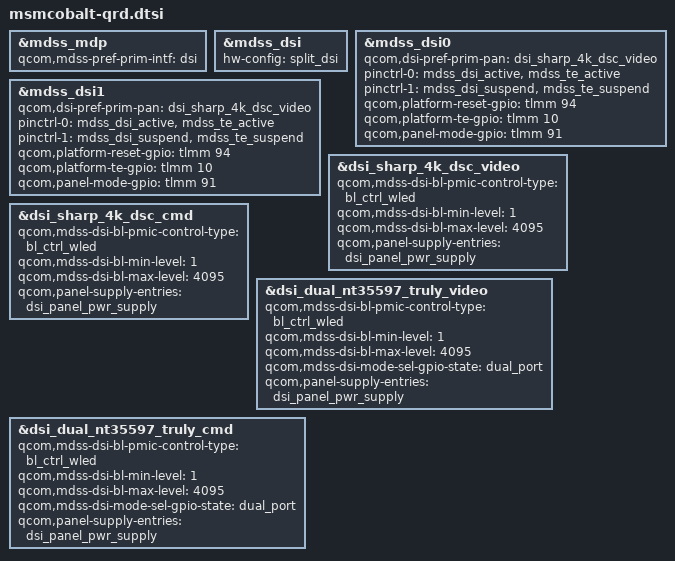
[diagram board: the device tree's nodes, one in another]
/* Copyright (c) 2016, The Linux Foundation. All rights reserved.
 *
 * This program is free software; you can redistribute it and/or modify
 * it under the terms of the GNU General Public License version 2 and
 * only version 2 as published by the Free Software Foundation.
 *
 * This program is distributed in the hope that it will be useful,
 * but WITHOUT ANY WARRANTY; without even the implied warranty of
 * MERCHANTABILITY or FITNESS FOR A PARTICULAR PURPOSE.  See the
 * GNU General Public License for more details.
 */

#include "msmcobalt-mtp.dtsi"

&mdss_mdp {
	qcom,mdss-pref-prim-intf = "dsi";
};

&mdss_dsi {
	hw-config = "split_dsi";
};

&mdss_dsi0 {
	qcom,dsi-pref-prim-pan = <&dsi_sharp_4k_dsc_video>;
	pinctrl-names = "mdss_default", "mdss_sleep";
	pinctrl-0 = <&mdss_dsi_active &mdss_te_active>;
	pinctrl-1 = <&mdss_dsi_suspend &mdss_te_suspend>;
	qcom,platform-reset-gpio = <&tlmm 94 0>;
	qcom,platform-te-gpio = <&tlmm 10 0>;
	qcom,panel-mode-gpio = <&tlmm 91 0>;
};

&mdss_dsi1 {
	qcom,dsi-pref-prim-pan = <&dsi_sharp_4k_dsc_video>;
	pinctrl-names = "mdss_default", "mdss_sleep";
	pinctrl-0 = <&mdss_dsi_active &mdss_te_active>;
	pinctrl-1 = <&mdss_dsi_suspend &mdss_te_suspend>;
	qcom,platform-reset-gpio = <&tlmm 94 0>;
	qcom,platform-te-gpio = <&tlmm 10 0>;
	qcom,panel-mode-gpio = <&tlmm 91 0>;
};

&dsi_sharp_4k_dsc_video {
	qcom,mdss-dsi-bl-pmic-control-type = "bl_ctrl_wled";
	qcom,mdss-dsi-bl-min-level = <1>;
	qcom,mdss-dsi-bl-max-level = <4095>;
	qcom,panel-supply-entries = <&dsi_panel_pwr_supply>;
};

&dsi_sharp_4k_dsc_cmd {
	qcom,mdss-dsi-bl-pmic-control-type = "bl_ctrl_wled";
	qcom,mdss-dsi-bl-min-level = <1>;
	qcom,mdss-dsi-bl-max-level = <4095>;
	qcom,panel-supply-entries = <&dsi_panel_pwr_supply>;
};

&dsi_dual_nt35597_truly_video {
	qcom,mdss-dsi-bl-pmic-control-type = "bl_ctrl_wled";
	qcom,mdss-dsi-bl-min-level = <1>;
	qcom,mdss-dsi-bl-max-level = <4095>;
	qcom,mdss-dsi-mode-sel-gpio-state = "dual_port";
	qcom,panel-supply-entries = <&dsi_panel_pwr_supply>;
};

&dsi_dual_nt35597_truly_cmd {
	qcom,mdss-dsi-bl-pmic-control-type = "bl_ctrl_wled";
	qcom,mdss-dsi-bl-min-level = <1>;
	qcom,mdss-dsi-bl-max-level = <4095>;
	qcom,mdss-dsi-mode-sel-gpio-state = "dual_port";
	qcom,panel-supply-entries = <&dsi_panel_pwr_supply>;
};
